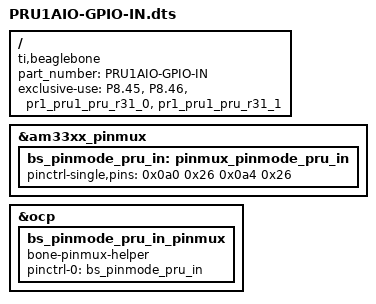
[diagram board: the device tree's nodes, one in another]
/*
 * This is a template-generated file from BoneScript
 */

/dts-v1/;
/plugin/;

/{
    compatible = "ti,beaglebone", "ti,beaglebone-black";
    part_number = "PRU1AIO-GPIO-IN";

    exclusive-use =
        "P8.45",
		"P8.46",
        "pr1_pru1_pru_r31_0",
		"pr1_pru1_pru_r31_1";

    fragment@0 {
        target = <&am33xx_pinmux>;
        __overlay__ {
            bs_pinmode_pru_in: pinmux_pinmode_pru_in {
                pinctrl-single,pins = <
					0x0a0 0x26 /* PowerOn 		r31.0	P8.45 */
					0x0a4 0x26 /* HeadLeftBump 	r31.1	P8.46 */
				>;
            };
        };
    };

    fragment@1 {
        target = <&ocp>;
        __overlay__ {
            bs_pinmode_pru_in_pinmux {
                compatible = "bone-pinmux-helper";
                status = "okay";
                pinctrl-names = "default";
                pinctrl-0 = <&bs_pinmode_pru_in>;
            };
        };
    };
};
